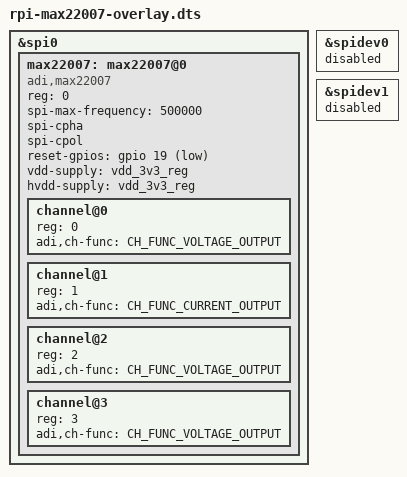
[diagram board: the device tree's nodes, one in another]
// SPDX-License-Identifier: GPL-2.0
/*
 * Analog Devices MAX22007
 *
 * Copyright (C) 2026 Analog Devices Inc.
 */

/dts-v1/;
/plugin/;

#include <dt-bindings/gpio/gpio.h>
#include <dt-bindings/iio/addac/adi,ad74413r.h>

&spi0 {
	#address-cells = <1>;
	#size-cells = <0>;
	status = "okay";

	max22007: max22007@0 {
		compatible = "adi,max22007";
		reg = <0>;
		spi-max-frequency = <500000>;
		spi-cpha;
		spi-cpol;
		status = "okay";
		reset-gpios = <&gpio 19 GPIO_ACTIVE_LOW>;
		vdd-supply = <&vdd_3v3_reg>;
		hvdd-supply = <&vdd_3v3_reg>;
		#address-cells = <1>;
		#size-cells = <0>;

		channel@0 {
			reg = <0>;
			adi,ch-func = <CH_FUNC_VOLTAGE_OUTPUT>;
		};

		channel@1 {
			reg = <1>;
			adi,ch-func = <CH_FUNC_CURRENT_OUTPUT>;
		};

		channel@2 {
			reg = <2>;
			adi,ch-func = <CH_FUNC_VOLTAGE_OUTPUT>;
		};

		channel@3 {
			reg = <3>;
			adi,ch-func = <CH_FUNC_VOLTAGE_OUTPUT>;
		};
	};
};

&spidev0 {
	status = "disabled";
};

&spidev1 {
	status = "disabled";
};
